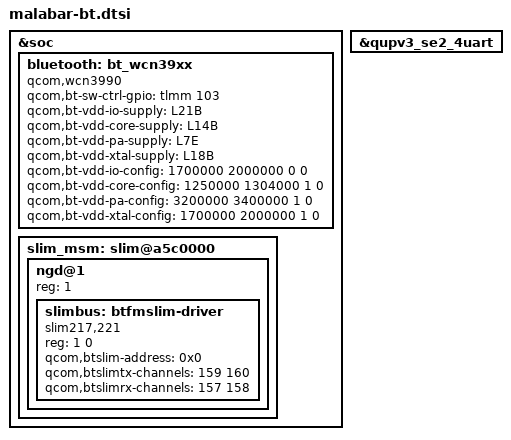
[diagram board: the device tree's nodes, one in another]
// SPDX-License-Identifier: BSD-3-Clause

/*
 * Copyright (c) Qualcomm Technologies, Inc. and/or its subsidiaries.
 */

#include <dt-bindings/interrupt-controller/arm-gic.h>
#include <dt-bindings/gpio/gpio.h>

&soc {
	bluetooth: bt_wcn39xx {
	compatible = "qcom,wcn3990";
		qcom,bt-sw-ctrl-gpio = <&tlmm 103 GPIO_ACTIVE_HIGH>;
		qcom,bt-vdd-io-supply = <&L21B>;  /* IO */
		qcom,bt-vdd-core-supply = <&L14B>; /* RFA */
		qcom,bt-vdd-pa-supply = <&L7E>; /* CHAIN0 / CH0 */
		qcom,bt-vdd-xtal-supply = <&L18B>; /* XO */

		qcom,bt-vdd-io-config = <1700000 2000000 0 0>;
		qcom,bt-vdd-core-config = <1250000 1304000 1 0>;
		qcom,bt-vdd-pa-config = <3200000 3400000 1 0>;
		qcom,bt-vdd-xtal-config = <1700000 2000000 1 0>;
	};

	// slim_msm instance from audio team
	slim_msm: slim@a5c0000 {
		status =  "ok";
		ngd@1 {
			reg = <1>;
			#address-cells = <1>;
			#size-cells = <1>;
			//slimbus child nodes
			slimbus: btfmslim-driver {
				compatible = "slim217,221";
				reg = <1 0>;
				qcom,btslim-address  = <0x0>;
				qcom,btslimtx-channels = <159 160>;
				qcom,btslimrx-channels = <157 158>;
			};
		};
	};

};

//uart instance
&qupv3_se2_4uart {
	status = "ok";
};

